AUTOSAR XML (schema 4-2-2)
package /AUTOSAR_NvM/PortInterfaces
  6 x client server interface, all with is-service=true:
    NvMAdmin
      operation SetBlockProtection: possible-error=NvMAdmin/E_NOT_OK
        arg ProtectionEnabled: type=boolean, direction=IN
      error E_NOT_OK: error-code=1
    NvMMirror
      operation ReadRamBlockFromNvM: possible-error=NvMMirror/E_NOT_OK
        arg SrcPtr: type=NvM_Rb_VoidPtr, direction=IN
      operation WriteRamBlockToNvM: possible-error=NvMMirror/E_NOT_OK
        arg DstPtr: type=NvM_Rb_VoidPtr, direction=IN
      error E_NOT_OK: error-code=1
    NvMNotifyInitBlock
      operation InitBlock: possible-error=NvMNotifyInitBlock/E_NOT_OK
      error E_NOT_OK: error-code=1
    NvMNotifyJobFinished
      operation JobFinished: possible-error=NvMNotifyJobFinished/E_NOT_OK
        arg ServiceId: type=uint8, direction=IN
        arg JobResult: type=NvM_RequestResultType, direction=IN
      error E_NOT_OK: error-code=1
    NvMRbNotifyJobStarted
      operation JobStarted
        arg ServiceId: type=uint8, direction=IN
    NvMService
      9 x operation, all with possible-error=NvMService/E_NOT_OK:
        EraseBlock
        GetDataIndex
          arg DataIndexPtr: type=uint8, direction=OUT
        GetErrorStatus
          arg RequestResultPtr: type=NvM_RequestResultType, direction=OUT
        InvalidateNvBlock
        ReadBlock
          arg DstPtr: type=NvM_Rb_VoidPtr, direction=IN
        RestoreBlockDefaults
          arg DstPtr: type=NvM_Rb_VoidPtr, direction=IN
        SetDataIndex
          arg DataIndex: type=uint8, direction=IN
        SetRamBlockStatus
          arg BlockChanged: type=boolean, direction=IN
        WriteBlock
          arg SrcPtr: type=NvM_Rb_ConstVoidPtr, direction=IN
      error E_NOT_OK: error-code=1
package /AUTOSAR_NvM/SwcImplementations
  swc implementation NvM: programming-language=C, swc-bsw-mapping=NvM, vendor-id=6, behavior=NVRAMManager
package /AUTOSAR_NvM/SwComponentTypes
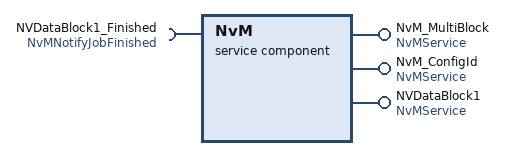
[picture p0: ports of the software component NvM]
  service sw component type NvM
    provide port NvM_MultiBlock: provided-interface=NvMService
    provide port NvM_ConfigId: provided-interface=NvMService
    provide port NVDataBlock1: provided-interface=NvMService
    require port NVDataBlock1_Finished: required-interface=NvMNotifyJobFinished
    behavior NVRAMManager
      27 x operation invoked event:
        EENB_NvM_MultiBlock: start-on-event=EraseNvBlock, operation=NvM_MultiBlock.EraseBlock
        EGDI_NvM_MultiBlock: start-on-event=GetDataIndex, operation=NvM_MultiBlock.GetDataIndex
        EGES_NvM_MultiBlock: start-on-event=GetErrorStatus, operation=NvM_MultiBlock.GetErrorStatus
        EINB_NvM_MultiBlock: start-on-event=InvalidateNvBlock, operation=NvM_MultiBlock.InvalidateNvBlock
        ERBL_NvM_MultiBlock: start-on-event=ReadBlock, operation=NvM_MultiBlock.ReadBlock
        ERBD_NvM_MultiBlock: start-on-event=RestoreBlockDefaults, operation=NvM_MultiBlock.RestoreBlockDefaults
        ESDI_NvM_MultiBlock: start-on-event=SetDataIndex, operation=NvM_MultiBlock.SetDataIndex
        ESRS_NvM_MultiBlock: start-on-event=SetRamBlockStatus, operation=NvM_MultiBlock.SetRamBlockStatus
        EWBL_NvM_MultiBlock: start-on-event=WriteBlock, operation=NvM_MultiBlock.WriteBlock
        EENB_NvM_ConfigId: start-on-event=EraseNvBlock, operation=NvM_ConfigId.EraseBlock
        EGDI_NvM_ConfigId: start-on-event=GetDataIndex, operation=NvM_ConfigId.GetDataIndex
        EGES_NvM_ConfigId: start-on-event=GetErrorStatus, operation=NvM_ConfigId.GetErrorStatus
        EINB_NvM_ConfigId: start-on-event=InvalidateNvBlock, operation=NvM_ConfigId.InvalidateNvBlock
        ERBL_NvM_ConfigId: start-on-event=ReadBlock, operation=NvM_ConfigId.ReadBlock
        ERBD_NvM_ConfigId: start-on-event=RestoreBlockDefaults, operation=NvM_ConfigId.RestoreBlockDefaults
        ESDI_NvM_ConfigId: start-on-event=SetDataIndex, operation=NvM_ConfigId.SetDataIndex
        ESRS_NvM_ConfigId: start-on-event=SetRamBlockStatus, operation=NvM_ConfigId.SetRamBlockStatus
        EWBL_NvM_ConfigId: start-on-event=WriteBlock, operation=NvM_ConfigId.WriteBlock
        EENB_NVDataBlock1: start-on-event=EraseNvBlock, operation=NVDataBlock1.EraseBlock
        EGDI_NVDataBlock1: start-on-event=GetDataIndex, operation=NVDataBlock1.GetDataIndex
        EGES_NVDataBlock1: start-on-event=GetErrorStatus, operation=NVDataBlock1.GetErrorStatus
        EINB_NVDataBlock1: start-on-event=InvalidateNvBlock, operation=NVDataBlock1.InvalidateNvBlock
        ERBL_NVDataBlock1: start-on-event=ReadBlock, operation=NVDataBlock1.ReadBlock
        ERBD_NVDataBlock1: start-on-event=RestoreBlockDefaults, operation=NVDataBlock1.RestoreBlockDefaults
        ESDI_NVDataBlock1: start-on-event=SetDataIndex, operation=NVDataBlock1.SetDataIndex
        ESRS_NVDataBlock1: start-on-event=SetRamBlockStatus, operation=NVDataBlock1.SetRamBlockStatus
        EWBL_NVDataBlock1: start-on-event=WriteBlock, operation=NVDataBlock1.WriteBlock
      port-api-options:
        {enable-take-address=false, indirect-api=false, port-defined-argument-value{value=0, value-type=NvM_BlockIdType}, port=NvM_MultiBlock}
        {enable-take-address=false, indirect-api=false, port-defined-argument-value{value=1, value-type=NvM_BlockIdType}, port=NvM_ConfigId}
        {enable-take-address=false, indirect-api=false, port-defined-argument-value{value=3, value-type=NvM_BlockIdType}, port=NVDataBlock1}
        enable-take-address=true, indirect-api=false, port=NVDataBlock1_Finished
      11 x runnable:
        EraseNvBlock: can-be-invoked-concurrently=true, symbol=NvM_EraseNvBlock
        GetDataIndex: can-be-invoked-concurrently=true, symbol=NvM_GetDataIndex
        GetErrorStatus: can-be-invoked-concurrently=true, symbol=NvM_GetErrorStatus
        InvalidateNvBlock: can-be-invoked-concurrently=true, symbol=NvM_InvalidateNvBlock
        ReadBlock: can-be-invoked-concurrently=true, symbol=NvM_ReadBlock
        RestoreBlockDefaults: can-be-invoked-concurrently=true, symbol=NvM_RestoreBlockDefaults
        SetBlockProtection: can-be-invoked-concurrently=true, symbol=NvM_SetBlockProtection
        SetDataIndex: can-be-invoked-concurrently=true, symbol=NvM_SetDataIndex
        SetRamBlockStatus: can-be-invoked-concurrently=true, symbol=NvM_SetRamBlockStatus
        WriteBlock: can-be-invoked-concurrently=true, symbol=NvM_WriteBlock
        MainFunction: symbol=NvM_MainFunction
          sync call SSCP_NVDataBlock1_Finished: operation=NVDataBlock1_Finished.JobFinished
